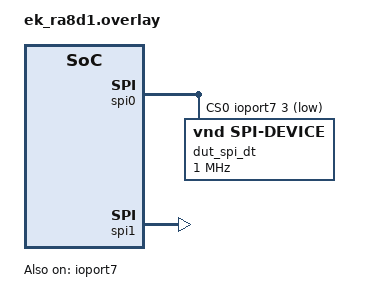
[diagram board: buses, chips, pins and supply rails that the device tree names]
/*
 * Copyright (c) 2025 Renesas Electronics Corporation
 * SPDX-License-Identifier: Apache-2.0
 */

&pinctrl {
	spi0_default: spi0_default {
		group1 {
			/* MISO MOSI RSPCK */
			psels = <RA_PSEL(RA_PSEL_SPI, 7, 0)>,
				<RA_PSEL(RA_PSEL_SPI, 7, 1)>,
				<RA_PSEL(RA_PSEL_SPI, 7, 2)>;
		};
	};
};

&ioport7 {
	status = "okay";
};

&spi0 {
	rx-dtc;
	tx-dtc;
	status = "okay";
	pinctrl-0 = <&spi0_default>;
	pinctrl-names = "default";
	cs-gpios = <&ioport7 3 GPIO_ACTIVE_LOW>;

	dut_spi_dt: test-spi-dev@0 {
		compatible = "vnd,spi-device";
		reg = <0>;
		spi-max-frequency = <1000000>;
	};
};

dut_spis: &spi1 {
	rx-dtc;
	tx-dtc;
	status = "okay";
};
